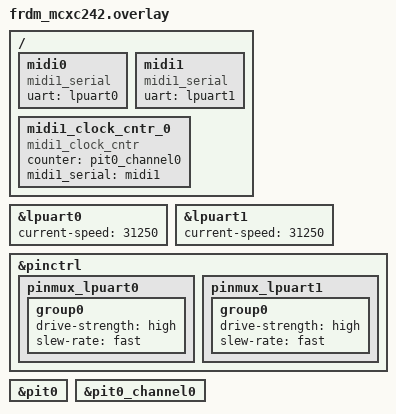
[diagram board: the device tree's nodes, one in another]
/*
 * SPDX-License-Identifier: Apache-2.0
 */

/**
 * @file frdm_mcxc242.overlay
 * @brief Combined overlay for hybrid MIDI test on MCXC242
 */

/ {
	/* Arduino header */
	midi0: midi0 {
		status = "okay";
		compatible = "midi1_serial";
		uart = <&lpuart0>;
	};
	/* MIKRObus */
	midi1: midi1 {
		status = "okay";
		compatible = "midi1_serial";
		uart = <&lpuart1>;
	};
	/*
	 * I am using the serial port on the MIKRObus so it does not interfere
	 * with logging on the console.
	 */
	midi1_clock_cntr_0: midi1_clock_cntr_0 {
		compatible = "midi1_clock_cntr";
		counter = <&pit0_channel0>;
		midi1_serial = <&midi1>;
		status = "okay";
	};
};

/* Arduino header */
&lpuart0 {
	status = "okay";
	current-speed = <31250>;
};

/* MIKRObus */
&lpuart1 {
	status = "okay";
	current-speed = <31250>;
};

/*
 * MIDI on a DIN5 plug is a current loop.
 * In my case I had to create a small driver PCB. Using a darlington in the
 * output and also using a opto-coupler for the input.
 */
&pinctrl {
	pinmux_lpuart0: pinmux_lpuart0 {
		group0 {
			/* Strongest drive + fast edges */
			drive-strength = "high";
			slew-rate = "fast";
		};
	};
	pinmux_lpuart1: pinmux_lpuart1 {
		group0 {
			/* Strongest drive + fast edges */
			drive-strength = "high";
			slew-rate = "fast";
		};
	};
};

&pit0 {
	status = "okay";
};

&pit0_channel0 {
	status = "okay";
};
